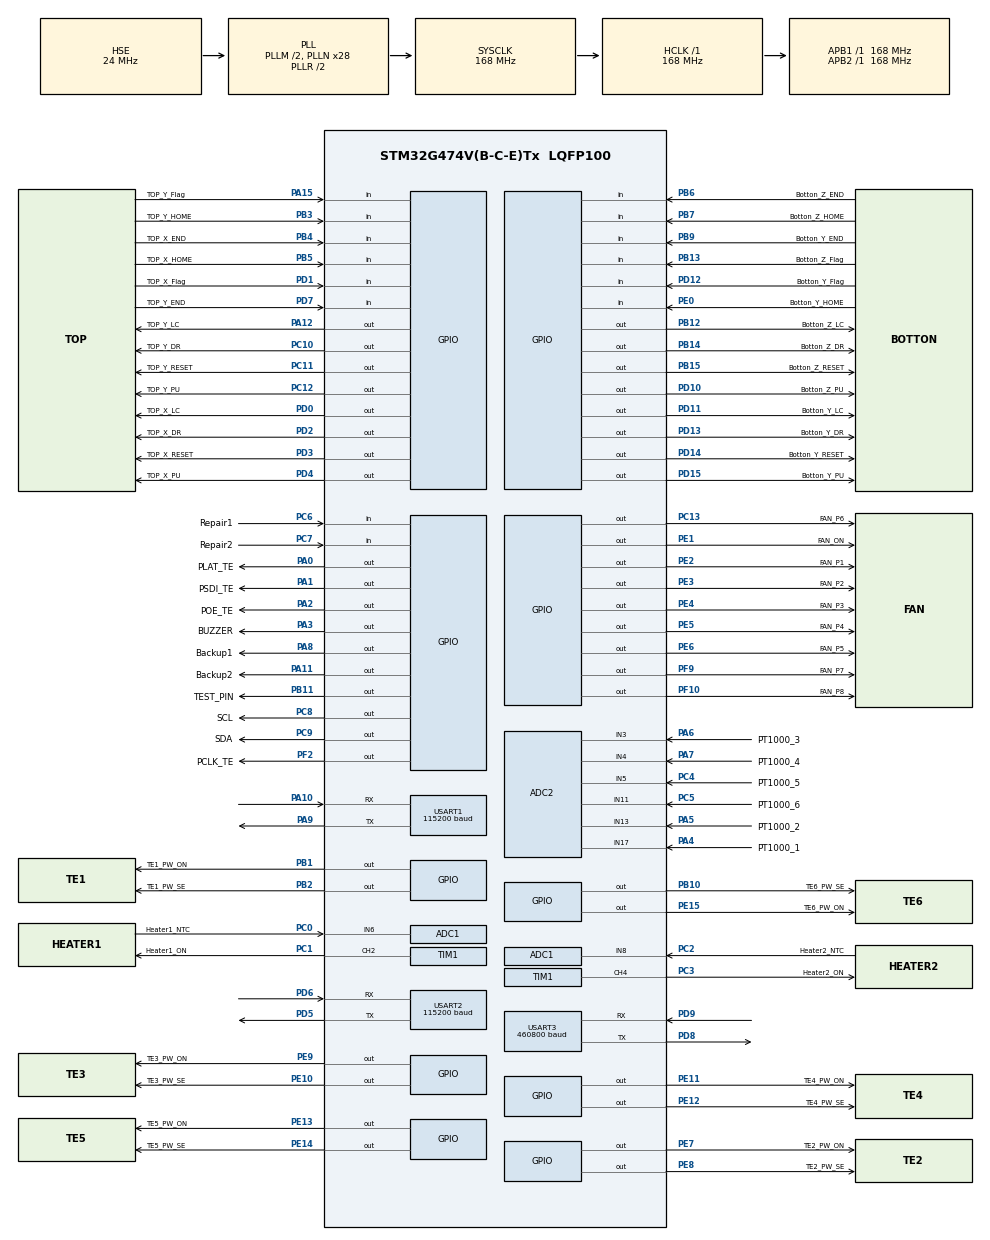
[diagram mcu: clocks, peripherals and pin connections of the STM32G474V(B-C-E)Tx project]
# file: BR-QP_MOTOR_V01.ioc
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ADC1.Channel-1\#ChannelRegularConversion=ADC_CHANNEL_6
ADC1.Channel-3\#ChannelRegularConversion=ADC_CHANNEL_8
ADC1.NbrOfConversion=2
ADC1.NbrOfConversionFlag=1
ADC1.OffsetNumber-3\#ChannelRegularConversion=ADC_OFFSET_NONE
ADC1.Rank-3\#ChannelRegularConversion=2
ADC1.SamplingTime-3\#ChannelRegularConversion=ADC_SAMPLETIME_2CYCLES_5
ADC1.master=1
ADC2.Channel-0\#ChannelRegularConversion=ADC_CHANNEL_17
ADC2.Channel-10\#ChannelRegularConversion=ADC_CHANNEL_11
ADC2.Channel-6\#ChannelRegularConversion=ADC_CHANNEL_13
ADC2.Channel-7\#ChannelRegularConversion=ADC_CHANNEL_3
ADC2.Channel-8\#ChannelRegularConversion=ADC_CHANNEL_4
ADC2.Channel-9\#ChannelRegularConversion=ADC_CHANNEL_5
ADC2.NbrOfConversion=6
ADC2.NbrOfConversionFlag=1
ADC2.OffsetNumber-10\#ChannelRegularConversion=ADC_OFFSET_NONE
ADC2.OffsetNumber-6\#ChannelRegularConversion=ADC_OFFSET_NONE
ADC2.OffsetNumber-7\#ChannelRegularConversion=ADC_OFFSET_NONE
ADC2.OffsetNumber-8\#ChannelRegularConversion=ADC_OFFSET_NONE
ADC2.OffsetNumber-9\#ChannelRegularConversion=ADC_OFFSET_NONE
ADC2.Rank-10\#ChannelRegularConversion=6
ADC2.Rank-6\#ChannelRegularConversion=2
ADC2.Rank-7\#ChannelRegularConversion=3
ADC2.Rank-8\#ChannelRegularConversion=4
ADC2.Rank-9\#ChannelRegularConversion=5
ADC2.SamplingTime-0\#ChannelRegularConversion=ADC_SAMPLETIME_47CYCLES_5
ADC2.SamplingTime-10\#ChannelRegularConversion=ADC_SAMPLETIME_47CYCLES_5
ADC2.SamplingTime-6\#ChannelRegularConversion=ADC_SAMPLETIME_47CYCLES_5
ADC2.SamplingTime-7\#ChannelRegularConversion=ADC_SAMPLETIME_47CYCLES_5
ADC2.SamplingTime-8\#ChannelRegularConversion=ADC_SAMPLETIME_2CYCLES_5
ADC2.SamplingTime-9\#ChannelRegularConversion=ADC_SAMPLETIME_47CYCLES_5
Dma.ADC1.0.Direction=DMA_PERIPH_TO_MEMORY
Dma.ADC1.0.EventEnable=DISABLE
Dma.ADC1.0.Instance=DMA1_Channel1
Dma.ADC1.0.MemDataAlignment=DMA_MDATAALIGN_HALFWORD
Dma.ADC1.0.MemInc=DMA_MINC_ENABLE
Dma.ADC1.0.Mode=DMA_NORMAL
Dma.ADC1.0.PeriphDataAlignment=DMA_PDATAALIGN_HALFWORD
Dma.ADC1.0.PeriphInc=DMA_PINC_DISABLE
Dma.ADC1.0.Polarity=HAL_DMAMUX_REQ_GEN_RISING
Dma.ADC1.0.Priority=DMA_PRIORITY_LOW
Dma.ADC1.0.RequestNumber=1
Dma.ADC1.0.SignalID=NONE
Dma.ADC1.0.SyncEnable=DISABLE
Dma.ADC1.0.SyncPolarity=HAL_DMAMUX_SYNC_NO_EVENT
Dma.ADC1.0.SyncRequestNumber=1
Dma.ADC1.0.SyncSignalID=NONE
Dma.ADC2.1.Direction=DMA_PERIPH_TO_MEMORY
Dma.ADC2.1.EventEnable=DISABLE
Dma.ADC2.1.Instance=DMA1_Channel2
Dma.ADC2.1.MemDataAlignment=DMA_MDATAALIGN_HALFWORD
Dma.ADC2.1.MemInc=DMA_MINC_ENABLE
Dma.ADC2.1.Mode=DMA_NORMAL
Dma.ADC2.1.PeriphDataAlignment=DMA_PDATAALIGN_HALFWORD
Dma.ADC2.1.PeriphInc=DMA_PINC_DISABLE
Dma.ADC2.1.Polarity=HAL_DMAMUX_REQ_GEN_RISING
Dma.ADC2.1.Priority=DMA_PRIORITY_LOW
Dma.ADC2.1.RequestNumber=1
Dma.ADC2.1.SignalID=NONE
Dma.ADC2.1.SyncEnable=DISABLE
Dma.ADC2.1.SyncPolarity=HAL_DMAMUX_SYNC_NO_EVENT
Dma.ADC2.1.SyncRequestNumber=1
Dma.ADC2.1.SyncSignalID=NONE
Dma.Request0=ADC1
Dma.Request1=ADC2
Mcu.Family=STM32G4
Mcu.Name=STM32G474V(B-C-E)Tx
Mcu.Package=LQFP100
NVIC.DMA1_Channel1_IRQn=true\:0\:0\:false\:false\:true\:false\:true\:true
NVIC.DMA1_Channel2_IRQn=true\:0\:0\:false\:false\:true\:false\:true\:true
NVIC.PriorityGroup=NVIC_PRIORITYGROUP_4
NVIC.TIM2_IRQn=true\:3\:0\:true\:false\:true\:true\:true\:true
NVIC.TIM3_IRQn=true\:0\:0\:false\:false\:true\:true\:true\:true
NVIC.TIM4_IRQn=true\:0\:0\:false\:false\:true\:true\:true\:true
NVIC.TIM5_IRQn=true\:0\:0\:false\:false\:true\:true\:true\:true
NVIC.TIM6_DAC_IRQn=true\:0\:0\:false\:false\:true\:true\:true\:true
NVIC.TIM7_DAC_IRQn=true\:0\:0\:false\:false\:true\:true\:true\:true
NVIC.USART1_IRQn=true\:1\:0\:true\:false\:true\:true\:true\:true
NVIC.USART2_IRQn=true\:2\:0\:true\:false\:true\:true\:true\:true
NVIC.USART3_IRQn=true\:0\:0\:true\:false\:true\:true\:true\:true
PA0.GPIO_Label=PLAT_TE
PA0.Signal=GPIO_Output
PA1.GPIO_Label=PSDI_TE
PA1.Signal=GPIO_Output
PA10.Mode=Asynchronous
PA10.Signal=USART1_RX
PA11.GPIO_Label=Backup2
PA11.Signal=GPIO_Output
PA12.GPIO_Label=TOP_Y_LC
PA12.Signal=GPIO_Output
PA15.GPIO_Label=TOP_Y_Flag
PA15.Signal=GPIO_Input
PA2.GPIO_Label=POE_TE
PA2.Signal=GPIO_Output
PA3.GPIO_Label=BUZZER
PA3.Signal=GPIO_Output
PA4.GPIO_Label=PT1000_1
PA4.GPIO_Mode=GPIO_MODE_ANALOG
PA4.GPIO_Pd=GPIO_NOPULL
PA4.Mode=IN17-Single-Ended
PA4.Signal=ADC2_IN17
PA5.GPIO_Label=PT1000_2
PA5.GPIO_Mode=GPIO_MODE_ANALOG
PA5.GPIO_Pd=GPIO_NOPULL
PA5.Mode=IN13-Single-Ended
PA5.Signal=ADC2_IN13
PA6.GPIO_Label=PT1000_3
PA6.GPIO_Mode=GPIO_MODE_ANALOG
PA6.GPIO_Pd=GPIO_NOPULL
PA6.Mode=IN3-Single-Ended
PA6.Signal=ADC2_IN3
PA7.GPIO_Label=PT1000_4
PA7.GPIO_Mode=GPIO_MODE_ANALOG
PA7.GPIO_Pd=GPIO_NOPULL
PA7.Mode=IN4-Single-Ended
PA7.Signal=ADC2_IN4
PA8.GPIO_Label=Backup1
PA8.Signal=GPIO_Output
PA9.Mode=Asynchronous
PA9.Signal=USART1_TX
PB1.GPIO_Label=TE1_PW_ON
PB1.Signal=GPIO_Output
PB10.GPIO_Label=TE6_PW_SE
PB10.Signal=GPIO_Output
PB11.GPIO_Label=TEST_PIN
PB11.Signal=GPIO_Output
PB12.GPIO_Label=Botton_Z_LC
PB12.Signal=GPIO_Output
PB13.GPIO_Label=Botton_Z_Flag
PB13.Signal=GPIO_Input
PB14.GPIO_Label=Botton_Z_DR
PB14.Signal=GPIO_Output
PB15.GPIO_Label=Botton_Z_RESET
PB15.Signal=GPIO_Output
PB2.GPIO_Label=TE1_PW_SE
PB2.Signal=GPIO_Output
PB3.GPIO_Label=TOP_Y_HOME
PB3.Signal=GPIO_Input
PB4.GPIO_Label=TOP_X_END
PB4.Signal=GPIO_Input
PB5.GPIO_Label=TOP_X_HOME
PB5.Signal=GPIO_Input
PB6.GPIO_Label=Botton_Z_END
PB6.Signal=GPIO_Input
PB7.GPIO_Label=Botton_Z_HOME
PB7.Signal=GPIO_Input
PB9.GPIO_Label=Botton_Y_END
PB9.Signal=GPIO_Input
PC0.GPIO_Label=Heater1_NTC
PC0.GPIO_Mode=GPIO_MODE_ANALOG
PC0.GPIO_Pd=GPIO_NOPULL
PC0.Mode=IN6-Single-Ended
PC0.Signal=ADC1_IN6
PC1.GPIO_Label=Heater1_ON
PC1.Signal=S_TIM1_CH2
PC10.GPIO_Label=TOP_Y_DR
PC10.Signal=GPIO_Output
PC11.GPIO_Label=TOP_Y_RESET
PC11.GPIO_PuPd=GPIO_PULLUP
PC11.Signal=GPIO_Output
PC12.GPIO_Label=TOP_Y_PU
PC12.Signal=GPIO_Output
PC13.GPIO_Label=FAN_P6
PC13.Signal=GPIO_Output
PC2.GPIO_Label=Heater2_NTC
PC2.GPIO_Mode=GPIO_MODE_ANALOG
PC2.GPIO_Pd=GPIO_NOPULL
PC2.Mode=IN8-Single-Ended
PC2.Signal=ADC1_IN8
PC3.GPIO_Label=Heater2_ON
PC3.Signal=S_TIM1_CH4
PC4.GPIO_Label=PT1000_5
PC4.GPIO_Mode=GPIO_MODE_ANALOG
PC4.GPIO_Pd=GPIO_NOPULL
PC4.Mode=IN5-Single-Ended
PC4.Signal=ADC2_IN5
PC5.GPIO_Label=PT1000_6
PC5.GPIO_Mode=GPIO_MODE_ANALOG
PC5.GPIO_Pd=GPIO_NOPULL
PC5.Mode=IN11-Single-Ended
PC5.Signal=ADC2_IN11
PC6.GPIO_Label=Repair1
PC6.Signal=GPIO_Input
PC7.GPIO_Label=Repair2
PC7.Signal=GPIO_Input
PC8.GPIO_Label=SCL
PC8.Signal=GPIO_Output
PC9.GPIO_Label=SDA
PC9.Signal=GPIO_Output
PD0.GPIO_Label=TOP_X_LC
PD0.Signal=GPIO_Output
PD1.GPIO_Label=TOP_X_Flag
PD1.Signal=GPIO_Input
PD10.GPIO_Label=Botton_Z_PU
PD10.Signal=GPIO_Output
PD11.GPIO_Label=Botton_Y_LC
PD11.Signal=GPIO_Output
PD12.GPIO_Label=Botton_Y_Flag
PD12.Signal=GPIO_Input
PD13.GPIO_Label=Botton_Y_DR
PD13.Signal=GPIO_Output
PD14.GPIO_Label=Botton_Y_RESET
PD14.Signal=GPIO_Output
PD15.GPIO_Label=Botton_Y_PU
PD15.Signal=GPIO_Output
PD2.GPIO_Label=TOP_X_DR
PD2.Signal=GPIO_Output
PD3.GPIO_Label=TOP_X_RESET
PD3.Signal=GPIO_Output
PD4.GPIO_Label=TOP_X_PU
PD4.Signal=GPIO_Output
PD5.Mode=Asynchronous
PD5.Signal=USART2_TX
PD6.Mode=Asynchronous
PD6.Signal=USART2_RX
PD7.GPIO_Label=TOP_Y_END
PD7.Signal=GPIO_Input
PD8.Mode=Asynchronous
PD8.Signal=USART3_TX
PD9.Mode=Asynchronous
PD9.Signal=USART3_RX
PE0.GPIO_Label=Botton_Y_HOME
PE0.Signal=GPIO_Input
PE1.GPIO_Label=FAN_ON
PE1.Signal=GPIO_Output
PE10.GPIO_Label=TE3_PW_SE
PE10.Signal=GPIO_Output
PE11.GPIO_Label=TE4_PW_ON
PE11.Signal=GPIO_Output
PE12.GPIO_Label=TE4_PW_SE
PE12.Signal=GPIO_Output
PE13.GPIO_Label=TE5_PW_ON
PE13.Signal=GPIO_Output
PE14.GPIO_Label=TE5_PW_SE
PE14.Signal=GPIO_Output
PE15.GPIO_Label=TE6_PW_ON
PE15.Signal=GPIO_Output
PE2.GPIO_Label=FAN_P1
PE2.Signal=GPIO_Output
PE3.GPIO_Label=FAN_P2
PE3.GPIO_PuPd=GPIO_PULLUP
PE3.PinState=GPIO_PIN_RESET
PE3.Signal=GPIO_Output
PE4.GPIO_Label=FAN_P3
PE4.GPIO_PuPd=GPIO_PULLUP
PE4.PinState=GPIO_PIN_RESET
PE4.Signal=GPIO_Output
PE5.GPIO_Label=FAN_P4
PE5.GPIO_PuPd=GPIO_PULLUP
PE5.PinState=GPIO_PIN_RESET
PE5.Signal=GPIO_Output
PE6.GPIO_Label=FAN_P5
PE6.Signal=GPIO_Output
PE7.GPIO_Label=TE2_PW_ON
PE7.Signal=GPIO_Output
PE8.GPIO_Label=TE2_PW_SE
PE8.Signal=GPIO_Output
PE9.GPIO_Label=TE3_PW_ON
PE9.Signal=GPIO_Output
PF0-OSC_IN.Mode=HSE-External-Oscillator
PF0-OSC_IN.Signal=RCC_OSC_IN
PF1-OSC_OUT.Mode=HSE-External-Oscillator
PF1-OSC_OUT.Signal=RCC_OSC_OUT
PF10.GPIO_Label=FAN_P8
PF10.Signal=GPIO_Output
PF2.GPIO_Label=PCLK_TE
PF2.Signal=GPIO_Output
PF9.GPIO_Label=FAN_P7
PF9.GPIO_PuPd=GPIO_PULLUP
PF9.Signal=GPIO_Output
ProjectManager.HeapSize=0x200
ProjectManager.StackSize=0x400
ProjectManager.TargetToolchain=STM32CubeIDE
RCC.ADC12Freq_Value=168000000
RCC.ADC345Freq_Value=168000000
RCC.AHBFreq_Value=168000000
RCC.APB1Freq_Value=168000000
RCC.APB1TimFreq_Value=168000000
RCC.APB2Freq_Value=168000000
RCC.APB2TimFreq_Value=168000000
RCC.CortexFreq_Value=168000000
RCC.EXTERNAL_CLOCK_VALUE=12288000
RCC.HCLKFreq_Value=168000000
RCC.HSE_VALUE=24000000
RCC.HSI48_VALUE=48000000
RCC.HSI_VALUE=16000000
RCC.LSE_VALUE=32768
RCC.PLLM=RCC_PLLM_DIV2
RCC.PLLN=28
RCC.PLLSourceVirtual=RCC_PLLSOURCE_HSE
RCC.SYSCLKFreq_VALUE=168000000
RCC.SYSCLKSource=RCC_SYSCLKSOURCE_PLLCLK
RCC.USBFreq_Value=168000000
RCC.VCOOutputFreq_Value=336000000
SH.S_TIM1_CH2.0=TIM1_CH2,PWM Generation2 CH2
SH.S_TIM1_CH4.0=TIM1_CH4,PWM Generation4 CH4
TIM1.AutoReloadPreload=TIM_AUTORELOAD_PRELOAD_DISABLE
TIM1.Channel-PWM\ Generation2\ CH2=TIM_CHANNEL_2
TIM1.Channel-PWM\ Generation4\ CH4=TIM_CHANNEL_4
TIM1.PeriodNoDither=5000-1
TIM1.Prescaler=33600
TIM2.AutoReloadPreload=TIM_AUTORELOAD_PRELOAD_DISABLE
TIM2.PeriodNoDither=60000-1
TIM2.Prescaler=28-1
TIM3.AutoReloadPreload=TIM_AUTORELOAD_PRELOAD_DISABLE
TIM3.PeriodNoDither=60000-1
TIM3.Prescaler=28-1
TIM4.PeriodNoDither=60000-1
TIM4.Prescaler=28-1
TIM5.PeriodNoDither=60000-1
TIM5.Prescaler=28-1
TIM6.PeriodNoDither=60000-1
TIM6.Prescaler=28-1
TIM7.PeriodNoDither=60000-1
TIM7.Prescaler=28-1
USART1.BaudRate=115200
USART1.VirtualMode-Asynchronous=VM_ASYNC
USART2.BaudRate=115200
USART2.VirtualMode-Asynchronous=VM_ASYNC
USART3.BaudRate=460800
USART3.VirtualMode-Asynchronous=VM_ASYNC
VP_SYS_VS_DBSignals.Mode=DisableDeadBatterySignals
VP_TIM2_VS_ClockSourceINT.Mode=Internal
VP_TIM3_VS_ClockSourceINT.Mode=Internal
VP_TIM4_VS_ClockSourceINT.Mode=Internal
VP_TIM5_VS_ClockSourceINT.Mode=Internal
VP_TIM6_VS_ClockSourceINT.Mode=Enable_Timer
VP_TIM7_VS_ClockSourceINT.Mode=Enable_Timer
board=custom

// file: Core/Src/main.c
/* USER CODE BEGIN Header */
/**
  ******************************************************************************
  * @file           : main.c
  * @brief          : Main program body
  ******************************************************************************
  * @attention
  *
  * Copyright (c) 2025 STMicroelectronics.
  * All rights reserved.
  *
  * This software is licensed under terms that can be found in the LICENSE file
  * in the root directory of this software component.
  * If no LICENSE file comes with this software, it is provided AS-IS.
  *
  ******************************************************************************
  */
/* USER CODE END Header */
#include "main.h"

ADC_HandleTypeDef hadc1;
ADC_HandleTypeDef hadc2;
DMA_HandleTypeDef hdma_adc1;
DMA_HandleTypeDef hdma_adc2;

TIM_HandleTypeDef htim1;
TIM_HandleTypeDef htim2;
TIM_HandleTypeDef htim3;
TIM_HandleTypeDef htim4;
TIM_HandleTypeDef htim5;
TIM_HandleTypeDef htim6;
TIM_HandleTypeDef htim7;

UART_HandleTypeDef huart1;
UART_HandleTypeDef huart2;
UART_HandleTypeDef huart3;

/* USER CODE BEGIN PV */
_ARISE_UART_OBJECT auart[UART_MAX];
uint8_t	xSys_UART_USB_Command[SIZE_OF_RX_BUF];
uint16_t time_count = 0;
uint8_t eep_read_flag = 0;
/* USER CODE END PV */

void SystemClock_Config(void);
static void MX_GPIO_Init(void);
static void MX_DMA_Init(void);
static void MX_USART1_UART_Init(void);
static void MX_USART2_UART_Init(void);
static void MX_USART3_UART_Init(void);
static void MX_TIM2_Init(void);
static void MX_TIM3_Init(void);
static void MX_TIM4_Init(void);
static void MX_TIM5_Init(void);
static void MX_ADC1_Init(void);
static void MX_ADC2_Init(void);
static void MX_TIM1_Init(void);
static void MX_TIM6_Init(void);
static void MX_TIM7_Init(void);

/* USER CODE BEGIN 0 */
//===========================================================================================
//UART 接收中斷
void HAL_UART_RxCpltCallback(UART_HandleTypeDef *huart)
{
	if(huart == auart[UART_USB].huarts)
	{
		Uart_Receive(&auart[UART_USB]);
		HAL_UART_Receive_IT(auart[UART_USB].huarts, &auart[UART_USB].r_data, 1);
	}
	else if(huart == auart[UART_DEBUG].huarts)
	{
		HAL_UART_Receive_IT(auart[UART_DEBUG].huarts, &auart[UART_DEBUG].r_data, 1);
	}
}

//===========================================================================================
//UART 傳送中斷
void HAL_UART_TxCpltCallback(UART_HandleTypeDef *huart)
{
	for(uint8_t i=0;i<UART_MAX;i++)
	{
		if(huart == auart[i].huarts)
		{
			Uart_Transmit(&auart[i],SOURCE_INTERRUPT);
		}
	}
}

//===========================================================================================
//Timer 中斷
void HAL_TIM_PeriodElapsedCallback(TIM_HandleTypeDef *htim)
{
  if(htim == &htim2)  //判斷中斷的是TIMER2
  {
	  TIMER_SET_RELOAD(TIMER2,60000-1);
    time_count++;  //10mS
    time_count%=50;
    if(time_count == 0)  //500ms
    {
      Set_Timer_Flag(FLAG_TIMER_500mS);
    }
    Set_Timer_Flag(FLAG_TIMER_10mS);
  }

  if(htim == &htim3)  //判斷中斷的是TIMER3
  {
    Buzzer_Trigger();
  }

  if(htim == &htim4)  //判斷中斷的是TIMER4
  {
	  CtrlM1_Trigger();
  }

  if(htim == &htim5)  //判斷中斷的是TIMER5
  {
	  CtrlM2_Trigger();
  }

  if(htim == &htim6)  //判斷中斷的是TIMER6
  {
	  CtrlM3_Trigger();
  }

  if(htim == &htim7)  //判斷中斷的是TIMER7
  {
	  CtrlM4_Trigger();
  }
}

/* USER CODE END 0 */

int main(void)
{

  /* MCU Configuration--------------------------------------------------------*/

  /* Reset of all peripherals, Initializes the Flash interface and the Systick. */
  HAL_Init();

  /* Configure the system clock */
  SystemClock_Config();

  /* Initialize all configured peripherals */
  MX_GPIO_Init();
  MX_DMA_Init();
  MX_USART1_UART_Init();
  MX_USART2_UART_Init();
  MX_USART3_UART_Init();
  MX_TIM2_Init();
  MX_TIM3_Init();
  MX_TIM4_Init();
  MX_TIM5_Init();
  MX_ADC1_Init();
  MX_ADC2_Init();
  MX_TIM1_Init();
  MX_TIM6_Init();
  MX_TIM7_Init();
  /* USER CODE BEGIN 2 */
  ADC_init();
  FAN_init();
  TE_init();
  heater_PWM_init();
  //UART變數INIT
  Uart_variable_Initial(auart,UART_MAX);
  //將STM32CUBE做出來的UART物件綁到結構變數的UART物件上
  //huart1-->表示電路圖上的UART1，輸出的位置為FT4233
  //huart2-->表示電路圖上的UART2，目前為TEST POINT，有需要就跳線出來用
  //huart3-->表示電路圖上的UART3，目前為debug port
  //auart[]-->這個結構陣列是UART的功能結構，陣列大小就是目前需求的UART數量，設計上有三組，陣列大小就是3
  //ARISE_UART_Bind就是把陣列的0、1、2綁定到huartX，只綁定目前需要的也可以，例如大小為3，只綁定兩個，沒有綁定的不要使用就好
  //綁定好以後就可以使用UART命令，後面帶入綁定的編號就可以了
  //例如
  //ARISE_UART_Bind(&auart[UART_USB],&huart3);  //UART_USB 綁定到 huart3
  //Send_LOG(UART_USB); //--> LOG就會從UART3送出
  //如果要改成UART1送出，只需要修改綁定
  //ARISE_UART_Bind(&auart[UART_USB],&huart1); // UART_USB 綁定到 huart1
  //注意，這個不能在程式中變動，會有不可預期的錯誤
  ARISE_UART_Bind(&auart[UART_USB],&huart1);
  ARISE_UART_Bind(&auart[UART_DEBUG],&huart3);
  //開啟，並設定接收中斷的數量、位置
  //綁定後，有需要使用到UART_HandleTypeDef物件的時候，可以直接使用auart[UART_USB].huarts
  //如此只需要修改綁定，就可以把整個應用的PORT都換掉
  HAL_UART_Receive_IT(auart[UART_USB].huarts, &auart[UART_USB].r_data, 1);
  HAL_UART_Receive_IT(auart[UART_DEBUG].huarts, &auart[UART_DEBUG].r_data, 1);
  //開啟TIMER 2中斷，系統時間用
  TIMER_ON(TIMER2);
  TIMER_SET_RELOAD(TIMER2,60000-1);
  FuncEE_Initial();
  Func_Disk_init();
  CtrlM1_Initial();
  CtrlM2_Initial();
  CtrlM3_Initial();
  CtrlM4_Initial();
  Buzzer_Init();
  UartOrder_Initial();
  SysFlag_Initial();
  eep_read_flag = FuncDisk_Test0(DISK_ACT_SAVE);
  FuncDisk_Test0(DISK_ACT_LOAD);
  Buzzer_Start(SOUNDS_DOREMI_SHORT,SOUNDS_DOREMI_SHORT_NUM);

//  FUNCTION SAMPLE
/*--------------------------------------------------------------------------------
 * 1.控制HEATER PWM
 * set_heater_PWM(HEATER_1,100); //表示 HEATER1 設定為100
 * set_heater_PWM(HEATER_2,100); //表示 HEATER1 設定為100
 * set_heater_PWM(HEATER_1,0);   //表示 HEATER1 關閉，沒有ON/OFF參數
 * set_heater_PWM(HEATER_2,0);   //表示 HEATER2 關閉，沒有ON/OFF參數
 *
 * 2.控制製冷晶片
 * set_SINGLE_TE_total(TE1,TE_ON,TE_HOT);  //設定TE1開啟，加熱
 * set_SINGLE_TE_power(TE1,255);		  //設定TE1強度255(最強)
 *
 * set_SINGLE_TE_total(TE3,TE_ON,TE_COLD);  //設定TE3開啟，製冷
 * set_SINGLE_TE_power(TE3,255);		  //設定TE3強度255(最強)
 *
 * set_SINGLE_TE_total(TE1,TE_OFF,TE_HOT);  //設定TE1關閉，
 * set_SINGLE_TE_power(TE1,0);        //關閉的話，最好設置POWER為0
 *
 * 3.設定風扇強度
 * set_FAN_total(FAN_ON,255);  //設定風扇開啟，強度255(最強)
 * set_FAN_total(FAN_OFF,0);   //設定風扇關閉，強度Don't care，但最好SET 0
 *
 * 4.讀取ADC值
 * read_ADC_value(ADC_HEATER_1)  //讀取heater1的"ADC值"，實際的溫度值需要校正和換算，ADC範圍為0-4095
 * *
 */

  //=========================================================
  //hardware test
  //needn't to send command
//  set_heater_PWM(HEATER_1,100); //表示 HEATER1 設定為100
//  set_heater_PWM(HEATER_2,100); //表示 HEATER1 設定為100
//  set_FAN_total(FAN_ON,128);  //設定風扇開啟，強度255(最強)
  /* USER CODE END 2 */

  /* Infinite loop */
  /* USER CODE BEGIN WHILE */
  while (1)
  {
    CtrlTask_Process();
    //這兩個要貼在一起，至少FLAG_UART_RECEIVED要放在FLAG_UART_USB_COMMAND的上面
    if(Get_Timer_Flag(FLAG_UART_RECEIVED))
    {
      Clear_Timer_Flag(FLAG_UART_RECEIVED);
      Uart_USB_Process(xSys_UART_USB_Command);
    }
    if (SysFlag_Get(FLAG_UART_USB_COMMAND))
    {
      Uart_USB_Order(xSys_UART_USB_Command);
    }

    if(SysFlag_Get(FLAG_REPORT_INFO))
    {
      UartAnswer_System_Info(UART_USB);
    }
    //500ms Task
    if(Get_Timer_Flag(FLAG_TIMER_500mS))
    {
      Clear_Timer_Flag(FLAG_TIMER_500mS);
      Send_LOG(UART_USB);
      Send_EEPROM(UART_USB);
//      Uart_Send_Text(UART_USB,(uint8_t *)"*00EEP");
//      Uart_Send_Value(UART_USB,(uint8_t *)":", eep_read_flag, 4);
//      Uart_Send_Text(UART_USB,(uint8_t *)":#%!\r\n");
    }
    //10mS Task
    if(Get_Timer_Flag(FLAG_TIMER_10mS))
    {
      Clear_Timer_Flag(FLAG_TIMER_10mS);
    }

    reflush_ADC_DMA();  //讓ADC和DMA重新執行
    /* USER CODE END WHILE */

  }
}

void SystemClock_Config(void)
{
  RCC_OscInitTypeDef RCC_OscInitStruct = {0};
  RCC_ClkInitTypeDef RCC_ClkInitStruct = {0};

  /** Configure the main internal regulator output voltage
  */
  HAL_PWREx_ControlVoltageScaling(PWR_REGULATOR_VOLTAGE_SCALE1_BOOST);

  /** Initializes the RCC Oscillators according to the specified parameters
  * in the RCC_OscInitTypeDef structure.
  */
  RCC_OscInitStruct.OscillatorType = RCC_OSCILLATORTYPE_HSE;
  RCC_OscInitStruct.HSEState = RCC_HSE_ON;
  RCC_OscInitStruct.PLL.PLLState = RCC_PLL_ON;
  RCC_OscInitStruct.PLL.PLLSource = RCC_PLLSOURCE_HSE;
  RCC_OscInitStruct.PLL.PLLM = RCC_PLLM_DIV2;
  RCC_OscInitStruct.PLL.PLLN = 28;
  RCC_OscInitStruct.PLL.PLLP = RCC_PLLP_DIV2;
  RCC_OscInitStruct.PLL.PLLQ = RCC_PLLQ_DIV2;
  RCC_OscInitStruct.PLL.PLLR = RCC_PLLR_DIV2;
  if (HAL_RCC_OscConfig(&RCC_OscInitStruct) != HAL_OK)
  {
    Error_Handler();
  }

  /** Initializes the CPU, AHB and APB buses clocks
  */
  RCC_ClkInitStruct.ClockType = RCC_CLOCKTYPE_HCLK|RCC_CLOCKTYPE_SYSCLK
                              |RCC_CLOCKTYPE_PCLK1|RCC_CLOCKTYPE_PCLK2;
  RCC_ClkInitStruct.SYSCLKSource = RCC_SYSCLKSOURCE_PLLCLK;
  RCC_ClkInitStruct.AHBCLKDivider = RCC_SYSCLK_DIV1;
  RCC_ClkInitStruct.APB1CLKDivider = RCC_HCLK_DIV1;
  RCC_ClkInitStruct.APB2CLKDivider = RCC_HCLK_DIV1;

  if (HAL_RCC_ClockConfig(&RCC_ClkInitStruct, FLASH_LATENCY_4) != HAL_OK)
  {
    Error_Handler();
  }
}

static void MX_ADC1_Init(void)
{

  ADC_MultiModeTypeDef multimode = {0};
  ADC_ChannelConfTypeDef sConfig = {0};

  /** Common config
  */
  hadc1.Instance = ADC1;
  hadc1.Init.ClockPrescaler = ADC_CLOCK_SYNC_PCLK_DIV4;
  hadc1.Init.Resolution = ADC_RESOLUTION_12B;
  hadc1.Init.DataAlign = ADC_DATAALIGN_RIGHT;
  hadc1.Init.GainCompensation = 0;
  hadc1.Init.ScanConvMode = ADC_SCAN_ENABLE;
  hadc1.Init.EOCSelection = ADC_EOC_SINGLE_CONV;
  hadc1.Init.LowPowerAutoWait = DISABLE;
  hadc1.Init.ContinuousConvMode = DISABLE;
  hadc1.Init.NbrOfConversion = 2;
  hadc1.Init.DiscontinuousConvMode = DISABLE;
  hadc1.Init.ExternalTrigConv = ADC_SOFTWARE_START;
  hadc1.Init.ExternalTrigConvEdge = ADC_EXTERNALTRIGCONVEDGE_NONE;
  hadc1.Init.DMAContinuousRequests = DISABLE;
  hadc1.Init.Overrun = ADC_OVR_DATA_PRESERVED;
  hadc1.Init.OversamplingMode = DISABLE;
  if (HAL_ADC_Init(&hadc1) != HAL_OK)
  {
    Error_Handler();
  }

  /** Configure the ADC multi-mode
  */
  multimode.Mode = ADC_MODE_INDEPENDENT;
  if (HAL_ADCEx_MultiModeConfigChannel(&hadc1, &multimode) != HAL_OK)
  {
    Error_Handler();
  }

  /** Configure Regular Channel
  */
  sConfig.Channel = ADC_CHANNEL_6;
  sConfig.Rank = ADC_REGULAR_RANK_1;
  sConfig.SamplingTime = ADC_SAMPLETIME_2CYCLES_5;
  sConfig.SingleDiff = ADC_SINGLE_ENDED;
  sConfig.OffsetNumber = ADC_OFFSET_NONE;
  sConfig.Offset = 0;
  if (HAL_ADC_ConfigChannel(&hadc1, &sConfig) != HAL_OK)
  {
    Error_Handler();
  }

  /** Configure Regular Channel
  */
  sConfig.Channel = ADC_CHANNEL_8;
  sConfig.Rank = ADC_REGULAR_RANK_2;
  if (HAL_ADC_ConfigChannel(&hadc1, &sConfig) != HAL_OK)
  {
    Error_Handler();
  }

}

static void MX_ADC2_Init(void)
{

  ADC_ChannelConfTypeDef sConfig = {0};

  /** Common config
  */
  hadc2.Instance = ADC2;
  hadc2.Init.ClockPrescaler = ADC_CLOCK_SYNC_PCLK_DIV4;
  hadc2.Init.Resolution = ADC_RESOLUTION_12B;
  hadc2.Init.DataAlign = ADC_DATAALIGN_RIGHT;
  hadc2.Init.GainCompensation = 0;
  hadc2.Init.ScanConvMode = ADC_SCAN_ENABLE;
  hadc2.Init.EOCSelection = ADC_EOC_SINGLE_CONV;
  hadc2.Init.LowPowerAutoWait = DISABLE;
  hadc2.Init.ContinuousConvMode = DISABLE;
  hadc2.Init.NbrOfConversion = 6;
  hadc2.Init.DiscontinuousConvMode = DISABLE;
  hadc2.Init.ExternalTrigConv = ADC_SOFTWARE_START;
  hadc2.Init.ExternalTrigConvEdge = ADC_EXTERNALTRIGCONVEDGE_NONE;
  hadc2.Init.DMAContinuousRequests = DISABLE;
  hadc2.Init.Overrun = ADC_OVR_DATA_PRESERVED;
  hadc2.Init.OversamplingMode = DISABLE;
  if (HAL_ADC_Init(&hadc2) != HAL_OK)
  {
    Error_Handler();
  }

  /** Configure Regular Channel
  */
  sConfig.Channel = ADC_CHANNEL_17;
  sConfig.Rank = ADC_REGULAR_RANK_1;
  sConfig.SamplingTime = ADC_SAMPLETIME_47CYCLES_5;
  sConfig.SingleDiff = ADC_SINGLE_ENDED;
  sConfig.OffsetNumber = ADC_OFFSET_NONE;
  sConfig.Offset = 0;
  if (HAL_ADC_ConfigChannel(&hadc2, &sConfig) != HAL_OK)
  {
    Error_Handler();
  }

  /** Configure Regular Channel
  */
  sConfig.Channel = ADC_CHANNEL_13;
  sConfig.Rank = ADC_REGULAR_RANK_2;
  if (HAL_ADC_ConfigChannel(&hadc2, &sConfig) != HAL_OK)
  {
    Error_Handler();
  }

  /** Configure Regular Channel
  */
  sConfig.Channel = ADC_CHANNEL_3;
  sConfig.Rank = ADC_REGULAR_RANK_3;
  if (HAL_ADC_ConfigChannel(&hadc2, &sConfig) != HAL_OK)
  {
    Error_Handler();
  }

  /** Configure Regular Channel
  */
  sConfig.Channel = ADC_CHANNEL_4;
  sConfig.Rank = ADC_REGULAR_RANK_4;
  sConfig.SamplingTime = ADC_SAMPLETIME_2CYCLES_5;
  if (HAL_ADC_ConfigChannel(&hadc2, &sConfig) != HAL_OK)
  {
    Error_Handler();
  }

  /** Configure Regular Channel
  */
  sConfig.Channel = ADC_CHANNEL_5;
  sConfig.Rank = ADC_REGULAR_RANK_5;
  sConfig.SamplingTime = ADC_SAMPLETIME_47CYCLES_5;
  if (HAL_ADC_ConfigChannel(&hadc2, &sConfig) != HAL_OK)
  {
    Error_Handler();
  }

  /** Configure Regular Channel
  */
  sConfig.Channel = ADC_CHANNEL_11;
  sConfig.Rank = ADC_REGULAR_RANK_6;
  if (HAL_ADC_ConfigChannel(&hadc2, &sConfig) != HAL_OK)
  {
    Error_Handler();
  }

}

static void MX_TIM1_Init(void)
{

  TIM_MasterConfigTypeDef sMasterConfig = {0};
  TIM_OC_InitTypeDef sConfigOC = {0};
  TIM_BreakDeadTimeConfigTypeDef sBreakDeadTimeConfig = {0};

  htim1.Instance = TIM1;
  htim1.Init.Prescaler = 33600;
  htim1.Init.CounterMode = TIM_COUNTERMODE_UP;
  htim1.Init.Period = 4999;
  htim1.Init.ClockDivision = TIM_CLOCKDIVISION_DIV1;
  htim1.Init.RepetitionCounter = 0;
  htim1.Init.AutoReloadPreload = TIM_AUTORELOAD_PRELOAD_DISABLE;
  if (HAL_TIM_PWM_Init(&htim1) != HAL_OK)
  {
    Error_Handler();
  }
  sMasterConfig.MasterOutputTrigger = TIM_TRGO_RESET;
  sMasterConfig.MasterOutputTrigger2 = TIM_TRGO2_RESET;
  sMasterConfig.MasterSlaveMode = TIM_MASTERSLAVEMODE_DISABLE;
  if (HAL_TIMEx_MasterConfigSynchronization(&htim1, &sMasterConfig) != HAL_OK)
  {
    Error_Handler();
  }
  sConfigOC.OCMode = TIM_OCMODE_PWM1;
  sConfigOC.Pulse = 0;
  sConfigOC.OCPolarity = TIM_OCPOLARITY_HIGH;
  sConfigOC.OCNPolarity = TIM_OCNPOLARITY_HIGH;
  sConfigOC.OCFastMode = TIM_OCFAST_DISABLE;
  sConfigOC.OCIdleState = TIM_OCIDLESTATE_RESET;
  sConfigOC.OCNIdleState = TIM_OCNIDLESTATE_RESET;
  if (HAL_TIM_PWM_ConfigChannel(&htim1, &sConfigOC, TIM_CHANNEL_2) != HAL_OK)
  {
    Error_Handler();
  }
  if (HAL_TIM_PWM_ConfigChannel(&htim1, &sConfigOC, TIM_CHANNEL_4) != HAL_OK)
  {
    Error_Handler();
  }
  sBreakDeadTimeConfig.OffStateRunMode = TIM_OSSR_DISABLE;
  sBreakDeadTimeConfig.OffStateIDLEMode = TIM_OSSI_DISABLE;
  sBreakDeadTimeConfig.LockLevel = TIM_LOCKLEVEL_OFF;
  sBreakDeadTimeConfig.DeadTime = 0;
  sBreakDeadTimeConfig.BreakState = TIM_BREAK_DISABLE;
  sBreakDeadTimeConfig.BreakPolarity = TIM_BREAKPOLARITY_HIGH;
  sBreakDeadTimeConfig.BreakFilter = 0;
  sBreakDeadTimeConfig.BreakAFMode = TIM_BREAK_AFMODE_INPUT;
  sBreakDeadTimeConfig.Break2State = TIM_BREAK2_DISABLE;
  sBreakDeadTimeConfig.Break2Polarity = TIM_BREAK2POLARITY_HIGH;
  sBreakDeadTimeConfig.Break2Filter = 0;
  sBreakDeadTimeConfig.Break2AFMode = TIM_BREAK_AFMODE_INPUT;
  sBreakDeadTimeConfig.AutomaticOutput = TIM_AUTOMATICOUTPUT_DISABLE;
  if (HAL_TIMEx_ConfigBreakDeadTime(&htim1, &sBreakDeadTimeConfig) != HAL_OK)
  {
    Error_Handler();
  }
  HAL_TIM_MspPostInit(&htim1);

}

static void MX_TIM2_Init(void)
{

  TIM_ClockConfigTypeDef sClockSourceConfig = {0};
  TIM_MasterConfigTypeDef sMasterConfig = {0};

  htim2.Instance = TIM2;
  htim2.Init.Prescaler = 28-1;
  htim2.Init.CounterMode = TIM_COUNTERMODE_UP;
  htim2.Init.Period = 59999;
  htim2.Init.ClockDivision = TIM_CLOCKDIVISION_DIV1;
  htim2.Init.AutoReloadPreload = TIM_AUTORELOAD_PRELOAD_DISABLE;
  if (HAL_TIM_Base_Init(&htim2) != HAL_OK)
  {
    Error_Handler();
  }
  sClockSourceConfig.ClockSource = TIM_CLOCKSOURCE_INTERNAL;
  if (HAL_TIM_ConfigClockSource(&htim2, &sClockSourceConfig) != HAL_OK)
  {
    Error_Handler();
  }
  sMasterConfig.MasterOutputTrigger = TIM_TRGO_RESET;
  sMasterConfig.MasterSlaveMode = TIM_MASTERSLAVEMODE_DISABLE;
  if (HAL_TIMEx_MasterConfigSynchronization(&htim2, &sMasterConfig) != HAL_OK)
  {
    Error_Handler();
  }

}

static void MX_TIM3_Init(void)
{

  TIM_ClockConfigTypeDef sClockSourceConfig = {0};
  TIM_MasterConfigTypeDef sMasterConfig = {0};

  htim3.Instance = TIM3;
  htim3.Init.Prescaler = 28-1;
  htim3.Init.CounterMode = TIM_COUNTERMODE_UP;
  htim3.Init.Period = 59999;
  htim3.Init.ClockDivision = TIM_CLOCKDIVISION_DIV1;
  htim3.Init.AutoReloadPreload = TIM_AUTORELOAD_PRELOAD_DISABLE;
  if (HAL_TIM_Base_Init(&htim3) != HAL_OK)
  {
    Error_Handler();
  }
  sClockSourceConfig.ClockSource = TIM_CLOCKSOURCE_INTERNAL;
  if (HAL_TIM_ConfigClockSource(&htim3, &sClockSourceConfig) != HAL_OK)
  {
    Error_Handler();
  }
  sMasterConfig.MasterOutputTrigger = TIM_TRGO_RESET;
  sMasterConfig.MasterSlaveMode = TIM_MASTERSLAVEMODE_DISABLE;
  if (HAL_TIMEx_MasterConfigSynchronization(&htim3, &sMasterConfig) != HAL_OK)
  {
    Error_Handler();
  }

}

static void MX_TIM4_Init(void)
{

  TIM_ClockConfigTypeDef sClockSourceConfig = {0};
  TIM_MasterConfigTypeDef sMasterConfig = {0};

  htim4.Instance = TIM4;
  htim4.Init.Prescaler = 28-1;
  htim4.Init.CounterMode = TIM_COUNTERMODE_UP;
  htim4.Init.Period = 59999;
  htim4.Init.ClockDivision = TIM_CLOCKDIVISION_DIV1;
  htim4.Init.AutoReloadPreload = TIM_AUTORELOAD_PRELOAD_DISABLE;
  if (HAL_TIM_Base_Init(&htim4) != HAL_OK)
  {
    Error_Handler();
  }
  sClockSourceConfig.ClockSource = TIM_CLOCKSOURCE_INTERNAL;
  if (HAL_TIM_ConfigClockSource(&htim4, &sClockSourceConfig) != HAL_OK)
  {
    Error_Handler();
  }
  sMasterConfig.MasterOutputTrigger = TIM_TRGO_RESET;
  sMasterConfig.MasterSlaveMode = TIM_MASTERSLAVEMODE_DISABLE;
  if (HAL_TIMEx_MasterConfigSynchronization(&htim4, &sMasterConfig) != HAL_OK)
  {
    Error_Handler();
  }

}

static void MX_TIM5_Init(void)
{

  TIM_ClockConfigTypeDef sClockSourceConfig = {0};
  TIM_MasterConfigTypeDef sMasterConfig = {0};

  htim5.Instance = TIM5;
  htim5.Init.Prescaler = 28-1;
  htim5.Init.CounterMode = TIM_COUNTERMODE_UP;
  htim5.Init.Period = 59999;
  htim5.Init.ClockDivision = TIM_CLOCKDIVISION_DIV1;
  htim5.Init.AutoReloadPreload = TIM_AUTORELOAD_PRELOAD_DISABLE;
  if (HAL_TIM_Base_Init(&htim5) != HAL_OK)
  {
    Error_Handler();
  }
  sClockSourceConfig.ClockSource = TIM_CLOCKSOURCE_INTERNAL;
  if (HAL_TIM_ConfigClockSource(&htim5, &sClockSourceConfig) != HAL_OK)
  {
    Error_Handler();
  }
  sMasterConfig.MasterOutputTrigger = TIM_TRGO_RESET;
  sMasterConfig.MasterSlaveMode = TIM_MASTERSLAVEMODE_DISABLE;
  if (HAL_TIMEx_MasterConfigSynchronization(&htim5, &sMasterConfig) != HAL_OK)
  {
    Error_Handler();
  }

}

static void MX_TIM6_Init(void)
{

  TIM_MasterConfigTypeDef sMasterConfig = {0};

  htim6.Instance = TIM6;
  htim6.Init.Prescaler = 28-1;
  htim6.Init.CounterMode = TIM_COUNTERMODE_UP;
  htim6.Init.Period = 59999;
  htim6.Init.AutoReloadPreload = TIM_AUTORELOAD_PRELOAD_DISABLE;
  if (HAL_TIM_Base_Init(&htim6) != HAL_OK)
  {
    Error_Handler();
  }
  sMasterConfig.MasterOutputTrigger = TIM_TRGO_RESET;
  sMasterConfig.MasterSlaveMode = TIM_MASTERSLAVEMODE_DISABLE;
  if (HAL_TIMEx_MasterConfigSynchronization(&htim6, &sMasterConfig) != HAL_OK)
  {
    Error_Handler();
  }

}

static void MX_TIM7_Init(void)
{

  TIM_MasterConfigTypeDef sMasterConfig = {0};

  htim7.Instance = TIM7;
  htim7.Init.Prescaler = 28-1;
  htim7.Init.CounterMode = TIM_COUNTERMODE_UP;
  htim7.Init.Period = 59999;
  htim7.Init.AutoReloadPreload = TIM_AUTORELOAD_PRELOAD_DISABLE;
  if (HAL_TIM_Base_Init(&htim7) != HAL_OK)
  {
    Error_Handler();
  }
  sMasterConfig.MasterOutputTrigger = TIM_TRGO_RESET;
  sMasterConfig.MasterSlaveMode = TIM_MASTERSLAVEMODE_DISABLE;
  if (HAL_TIMEx_MasterConfigSynchronization(&htim7, &sMasterConfig) != HAL_OK)
  {
    Error_Handler();
  }

}

static void MX_USART1_UART_Init(void)
{

  huart1.Instance = USART1;
  huart1.Init.BaudRate = 115200;
  huart1.Init.WordLength = UART_WORDLENGTH_8B;
  huart1.Init.StopBits = UART_STOPBITS_1;
  huart1.Init.Parity = UART_PARITY_NONE;
  huart1.Init.Mode = UART_MODE_TX_RX;
  huart1.Init.HwFlowCtl = UART_HWCONTROL_NONE;
  huart1.Init.OverSampling = UART_OVERSAMPLING_16;
  huart1.Init.OneBitSampling = UART_ONE_BIT_SAMPLE_DISABLE;
  huart1.Init.ClockPrescaler = UART_PRESCALER_DIV1;
  huart1.AdvancedInit.AdvFeatureInit = UART_ADVFEATURE_NO_INIT;
  if (HAL_UART_Init(&huart1) != HAL_OK)
  {
    Error_Handler();
  }
  if (HAL_UARTEx_SetTxFifoThreshold(&huart1, UART_TXFIFO_THRESHOLD_1_8) != HAL_OK)
  {
    Error_Handler();
  }
  if (HAL_UARTEx_SetRxFifoThreshold(&huart1, UART_RXFIFO_THRESHOLD_1_8) != HAL_OK)
  {
    Error_Handler();
  }
  if (HAL_UARTEx_DisableFifoMode(&huart1) != HAL_OK)
  {
    Error_Handler();
  }

}

static void MX_USART2_UART_Init(void)
{

  huart2.Instance = USART2;
  huart2.Init.BaudRate = 115200;
  huart2.Init.WordLength = UART_WORDLENGTH_8B;
  huart2.Init.StopBits = UART_STOPBITS_1;
  huart2.Init.Parity = UART_PARITY_NONE;
  huart2.Init.Mode = UART_MODE_TX_RX;
  huart2.Init.HwFlowCtl = UART_HWCONTROL_NONE;
  huart2.Init.OverSampling = UART_OVERSAMPLING_16;
  huart2.Init.OneBitSampling = UART_ONE_BIT_SAMPLE_DISABLE;
  huart2.Init.ClockPrescaler = UART_PRESCALER_DIV1;
  huart2.AdvancedInit.AdvFeatureInit = UART_ADVFEATURE_NO_INIT;
  if (HAL_UART_Init(&huart2) != HAL_OK)
  {
    Error_Handler();
  }
  if (HAL_UARTEx_SetTxFifoThreshold(&huart2, UART_TXFIFO_THRESHOLD_1_8) != HAL_OK)
  {
    Error_Handler();
  }
  if (HAL_UARTEx_SetRxFifoThreshold(&huart2, UART_RXFIFO_THRESHOLD_1_8) != HAL_OK)
  {
    Error_Handler();
  }
  if (HAL_UARTEx_DisableFifoMode(&huart2) != HAL_OK)
  {
    Error_Handler();
  }

}

static void MX_USART3_UART_Init(void)
{

  huart3.Instance = USART3;
  huart3.Init.BaudRate = 460800;
  huart3.Init.WordLength = UART_WORDLENGTH_8B;
  huart3.Init.StopBits = UART_STOPBITS_1;
  huart3.Init.Parity = UART_PARITY_NONE;
  huart3.Init.Mode = UART_MODE_TX_RX;
  huart3.Init.HwFlowCtl = UART_HWCONTROL_NONE;
  huart3.Init.OverSampling = UART_OVERSAMPLING_16;
  huart3.Init.OneBitSampling = UART_ONE_BIT_SAMPLE_DISABLE;
  huart3.Init.ClockPrescaler = UART_PRESCALER_DIV1;
  huart3.AdvancedInit.AdvFeatureInit = UART_ADVFEATURE_NO_INIT;
  if (HAL_UART_Init(&huart3) != HAL_OK)
  {
    Error_Handler();
  }
  if (HAL_UARTEx_SetTxFifoThreshold(&huart3, UART_TXFIFO_THRESHOLD_1_8) != HAL_OK)
  {
    Error_Handler();
  }
  if (HAL_UARTEx_SetRxFifoThreshold(&huart3, UART_RXFIFO_THRESHOLD_1_8) != HAL_OK)
  {
    Error_Handler();
  }
  if (HAL_UARTEx_DisableFifoMode(&huart3) != HAL_OK)
  {
    Error_Handler();
  }

}

static void MX_DMA_Init(void)
{

  /* DMA controller clock enable */
  __HAL_RCC_DMAMUX1_CLK_ENABLE();
  __HAL_RCC_DMA1_CLK_ENABLE();

  /* DMA interrupt init */
  /* DMA1_Channel1_IRQn interrupt configuration */
  HAL_NVIC_SetPriority(DMA1_Channel1_IRQn, 0, 0);
  HAL_NVIC_EnableIRQ(DMA1_Channel1_IRQn);
  /* DMA1_Channel2_IRQn interrupt configuration */
  HAL_NVIC_SetPriority(DMA1_Channel2_IRQn, 0, 0);
  HAL_NVIC_EnableIRQ(DMA1_Channel2_IRQn);

}

static void MX_GPIO_Init(void)
{
  GPIO_InitTypeDef GPIO_InitStruct = {0};

  /* GPIO Ports Clock Enable */
  __HAL_RCC_GPIOE_CLK_ENABLE();
  __HAL_RCC_GPIOC_CLK_ENABLE();
  __HAL_RCC_GPIOF_CLK_ENABLE();
  __HAL_RCC_GPIOA_CLK_ENABLE();
  __HAL_RCC_GPIOB_CLK_ENABLE();
  __HAL_RCC_GPIOD_CLK_ENABLE();

  /*Configure GPIO pin Output Level */
  HAL_GPIO_WritePin(GPIOE, FAN_P1_Pin|FAN_P2_Pin|FAN_P3_Pin|FAN_P4_Pin
                          |FAN_P5_Pin|TE2_PW_ON_Pin|TE2_PW_SE_Pin|TE3_PW_ON_Pin
                          |TE3_PW_SE_Pin|TE4_PW_ON_Pin|TE4_PW_SE_Pin|TE5_PW_ON_Pin
                          |TE5_PW_SE_Pin|TE6_PW_ON_Pin|FAN_ON_Pin, GPIO_PIN_RESET);

  /*Configure GPIO pin Output Level */
  HAL_GPIO_WritePin(GPIOC, FAN_P6_Pin|SCL_Pin|SDA_Pin|TOP_Y_DR_Pin
                          |TOP_Y_RESET_Pin|TOP_Y_PU_Pin, GPIO_PIN_RESET);

  /*Configure GPIO pin Output Level */
  HAL_GPIO_WritePin(GPIOF, FAN_P7_Pin|FAN_P8_Pin|PCLK_TE_Pin, GPIO_PIN_RESET);

  /*Configure GPIO pin Output Level */
  HAL_GPIO_WritePin(GPIOA, PLAT_TE_Pin|PSDI_TE_Pin|POE_TE_Pin|BUZZER_Pin
                          |Backup1_Pin|Backup2_Pin|TOP_Y_LC_Pin, GPIO_PIN_RESET);

  /*Configure GPIO pin Output Level */
  HAL_GPIO_WritePin(GPIOB, TE1_PW_ON_Pin|TE1_PW_SE_Pin|TE6_PW_SE_Pin|TEST_PIN_Pin
                          |Botton_Z_LC_Pin|Botton_Z_DR_Pin|Botton_Z_RESET_Pin, GPIO_PIN_RESET);

  /*Configure GPIO pin Output Level */
  HAL_GPIO_WritePin(GPIOD, Botton_Z_PU_Pin|Botton_Y_LC_Pin|Botton_Y_DR_Pin|Botton_Y_RESET_Pin
                          |Botton_Y_PU_Pin|TOP_X_LC_Pin|TOP_X_DR_Pin|TOP_X_RESET_Pin
                          |TOP_X_PU_Pin, GPIO_PIN_RESET);

  /*Configure GPIO pins : FAN_P1_Pin FAN_P5_Pin TE2_PW_ON_Pin TE2_PW_SE_Pin
                           TE3_PW_ON_Pin TE3_PW_SE_Pin TE4_PW_ON_Pin TE4_PW_SE_Pin
                           TE5_PW_ON_Pin TE5_PW_SE_Pin TE6_PW_ON_Pin FAN_ON_Pin */
  GPIO_InitStruct.Pin = FAN_P1_Pin|FAN_P5_Pin|TE2_PW_ON_Pin|TE2_PW_SE_Pin
                          |TE3_PW_ON_Pin|TE3_PW_SE_Pin|TE4_PW_ON_Pin|TE4_PW_SE_Pin
                          |TE5_PW_ON_Pin|TE5_PW_SE_Pin|TE6_PW_ON_Pin|FAN_ON_Pin;
  GPIO_InitStruct.Mode = GPIO_MODE_OUTPUT_PP;
  GPIO_InitStruct.Pull = GPIO_NOPULL;
  GPIO_InitStruct.Speed = GPIO_SPEED_FREQ_LOW;
  HAL_GPIO_Init(GPIOE, &GPIO_InitStruct);

  /*Configure GPIO pins : FAN_P2_Pin FAN_P3_Pin FAN_P4_Pin */
  GPIO_InitStruct.Pin = FAN_P2_Pin|FAN_P3_Pin|FAN_P4_Pin;
  GPIO_InitStruct.Mode = GPIO_MODE_OUTPUT_PP;
  GPIO_InitStruct.Pull = GPIO_PULLUP;
  GPIO_InitStruct.Speed = GPIO_SPEED_FREQ_LOW;
  HAL_GPIO_Init(GPIOE, &GPIO_InitStruct);

  /*Configure GPIO pins : FAN_P6_Pin SCL_Pin SDA_Pin TOP_Y_DR_Pin
                           TOP_Y_PU_Pin */
  GPIO_InitStruct.Pin = FAN_P6_Pin|SCL_Pin|SDA_Pin|TOP_Y_DR_Pin
                          |TOP_Y_PU_Pin;
  GPIO_InitStruct.Mode = GPIO_MODE_OUTPUT_PP;
  GPIO_InitStruct.Pull = GPIO_NOPULL;
  GPIO_InitStruct.Speed = GPIO_SPEED_FREQ_LOW;
  HAL_GPIO_Init(GPIOC, &GPIO_InitStruct);

  /*Configure GPIO pin : FAN_P7_Pin */
  GPIO_InitStruct.Pin = FAN_P7_Pin;
  GPIO_InitStruct.Mode = GPIO_MODE_OUTPUT_PP;
  GPIO_InitStruct.Pull = GPIO_PULLUP;
  GPIO_InitStruct.Speed = GPIO_SPEED_FREQ_LOW;
  HAL_GPIO_Init(FAN_P7_GPIO_Port, &GPIO_InitStruct);

  /*Configure GPIO pins : FAN_P8_Pin PCLK_TE_Pin */
  GPIO_InitStruct.Pin = FAN_P8_Pin|PCLK_TE_Pin;
  GPIO_InitStruct.Mode = GPIO_MODE_OUTPUT_PP;
  GPIO_InitStruct.Pull = GPIO_NOPULL;
  GPIO_InitStruct.Speed = GPIO_SPEED_FREQ_LOW;
  HAL_GPIO_Init(GPIOF, &GPIO_InitStruct);

  /*Configure GPIO pins : PLAT_TE_Pin PSDI_TE_Pin POE_TE_Pin BUZZER_Pin
                           Backup1_Pin Backup2_Pin TOP_Y_LC_Pin */
  GPIO_InitStruct.Pin = PLAT_TE_Pin|PSDI_TE_Pin|POE_TE_Pin|BUZZER_Pin
                          |Backup1_Pin|Backup2_Pin|TOP_Y_LC_Pin;
  GPIO_InitStruct.Mode = GPIO_MODE_OUTPUT_PP;
  GPIO_InitStruct.Pull = GPIO_NOPULL;
  GPIO_InitStruct.Speed = GPIO_SPEED_FREQ_LOW;
  HAL_GPIO_Init(GPIOA, &GPIO_InitStruct);

  /*Configure GPIO pins : TE1_PW_ON_Pin TE1_PW_SE_Pin TE6_PW_SE_Pin TEST_PIN_Pin
                           Botton_Z_LC_Pin Botton_Z_DR_Pin Botton_Z_RESET_Pin */
  GPIO_InitStruct.Pin = TE1_PW_ON_Pin|TE1_PW_SE_Pin|TE6_PW_SE_Pin|TEST_PIN_Pin
                          |Botton_Z_LC_Pin|Botton_Z_DR_Pin|Botton_Z_RESET_Pin;
  GPIO_InitStruct.Mode = GPIO_MODE_OUTPUT_PP;
  GPIO_InitStruct.Pull = GPIO_NOPULL;
  GPIO_InitStruct.Speed = GPIO_SPEED_FREQ_LOW;
  HAL_GPIO_Init(GPIOB, &GPIO_InitStruct);

  /*Configure GPIO pins : Botton_Z_Flag_Pin TOP_Y_HOME_Pin TOP_X_END_Pin TOP_X_HOME_Pin
                           Botton_Z_END_Pin Botton_Z_HOME_Pin Botton_Y_END_Pin */
  GPIO_InitStruct.Pin = Botton_Z_Flag_Pin|TOP_Y_HOME_Pin|TOP_X_END_Pin|TOP_X_HOME_Pin
                          |Botton_Z_END_Pin|Botton_Z_HOME_Pin|Botton_Y_END_Pin;
  GPIO_InitStruct.Mode = GPIO_MODE_INPUT;
  GPIO_InitStruct.Pull = GPIO_NOPULL;
  HAL_GPIO_Init(GPIOB, &GPIO_InitStruct);

  /*Configure GPIO pins : Botton_Z_PU_Pin Botton_Y_LC_Pin Botton_Y_DR_Pin Botton_Y_RESET_Pin
                           Botton_Y_PU_Pin TOP_X_LC_Pin TOP_X_DR_Pin TOP_X_RESET_Pin
                           TOP_X_PU_Pin */
  GPIO_InitStruct.Pin = Botton_Z_PU_Pin|Botton_Y_LC_Pin|Botton_Y_DR_Pin|Botton_Y_RESET_Pin
                          |Botton_Y_PU_Pin|TOP_X_LC_Pin|TOP_X_DR_Pin|TOP_X_RESET_Pin
                          |TOP_X_PU_Pin;
  GPIO_InitStruct.Mode = GPIO_MODE_OUTPUT_PP;
  GPIO_InitStruct.Pull = GPIO_NOPULL;
  GPIO_InitStruct.Speed = GPIO_SPEED_FREQ_LOW;
  HAL_GPIO_Init(GPIOD, &GPIO_InitStruct);

  /*Configure GPIO pins : Botton_Y_Flag_Pin TOP_X_Flag_Pin TOP_Y_END_Pin */
  GPIO_InitStruct.Pin = Botton_Y_Flag_Pin|TOP_X_Flag_Pin|TOP_Y_END_Pin;
  GPIO_InitStruct.Mode = GPIO_MODE_INPUT;
  GPIO_InitStruct.Pull = GPIO_NOPULL;
  HAL_GPIO_Init(GPIOD, &GPIO_InitStruct);

  /*Configure GPIO pins : Repair1_Pin Repair2_Pin */
  GPIO_InitStruct.Pin = Repair1_Pin|Repair2_Pin;
  GPIO_InitStruct.Mode = GPIO_MODE_INPUT;
  GPIO_InitStruct.Pull = GPIO_NOPULL;
  HAL_GPIO_Init(GPIOC, &GPIO_InitStruct);

  /*Configure GPIO pin : TOP_Y_Flag_Pin */
  GPIO_InitStruct.Pin = TOP_Y_Flag_Pin;
  GPIO_InitStruct.Mode = GPIO_MODE_INPUT;
  GPIO_InitStruct.Pull = GPIO_NOPULL;
  HAL_GPIO_Init(TOP_Y_Flag_GPIO_Port, &GPIO_InitStruct);

  /*Configure GPIO pin : TOP_Y_RESET_Pin */
  GPIO_InitStruct.Pin = TOP_Y_RESET_Pin;
  GPIO_InitStruct.Mode = GPIO_MODE_OUTPUT_PP;
  GPIO_InitStruct.Pull = GPIO_PULLUP;
  GPIO_InitStruct.Speed = GPIO_SPEED_FREQ_LOW;
  HAL_GPIO_Init(TOP_Y_RESET_GPIO_Port, &GPIO_InitStruct);

  /*Configure GPIO pin : Botton_Y_HOME_Pin */
  GPIO_InitStruct.Pin = Botton_Y_HOME_Pin;
  GPIO_InitStruct.Mode = GPIO_MODE_INPUT;
  GPIO_InitStruct.Pull = GPIO_NOPULL;
  HAL_GPIO_Init(Botton_Y_HOME_GPIO_Port, &GPIO_InitStruct);

}

void Error_Handler(void)
{
  __disable_irq();
  while (1)
  {
  }
}
